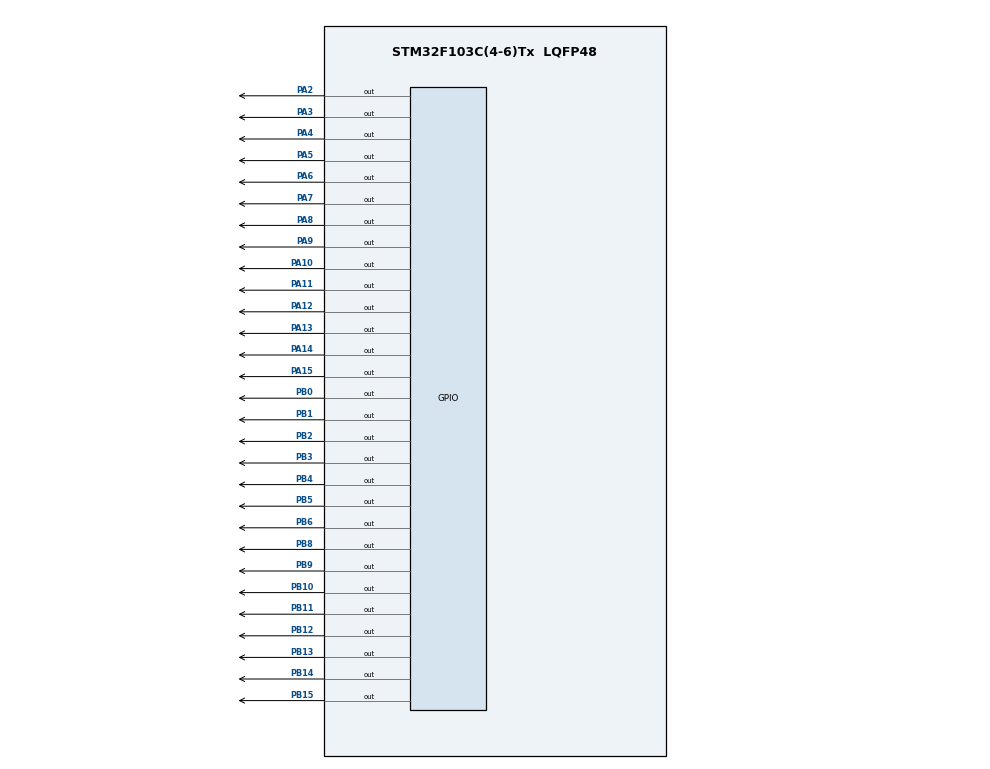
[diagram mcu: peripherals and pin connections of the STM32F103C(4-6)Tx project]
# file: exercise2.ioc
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Mcu.Family=STM32F1
Mcu.Name=STM32F103C(4-6)Tx
Mcu.Package=LQFP48
NVIC.PriorityGroup=NVIC_PRIORITYGROUP_4
NVIC.TIM2_IRQn=true\:0\:0\:false\:false\:true\:true\:true
PA10.Signal=GPIO_Output
PA11.Signal=GPIO_Output
PA12.Signal=GPIO_Output
PA13.Signal=GPIO_Output
PA14.Signal=GPIO_Output
PA15.Signal=GPIO_Output
PA2.Signal=GPIO_Output
PA3.Signal=GPIO_Output
PA4.Signal=GPIO_Output
PA5.Signal=GPIO_Output
PA6.Signal=GPIO_Output
PA7.Signal=GPIO_Output
PA8.Signal=GPIO_Output
PA9.Signal=GPIO_Output
PB0.Signal=GPIO_Output
PB1.Signal=GPIO_Output
PB10.Signal=GPIO_Output
PB11.Signal=GPIO_Output
PB12.Signal=GPIO_Output
PB13.Signal=GPIO_Output
PB14.Signal=GPIO_Output
PB15.Signal=GPIO_Output
PB2.Signal=GPIO_Output
PB3.Signal=GPIO_Output
PB4.Signal=GPIO_Output
PB5.Signal=GPIO_Output
PB6.Signal=GPIO_Output
PB8.Signal=GPIO_Output
PB9.Signal=GPIO_Output
ProjectManager.HeapSize=0x200
ProjectManager.StackSize=0x400
ProjectManager.TargetToolchain=STM32CubeIDE
RCC.APB1Freq_Value=8000000
RCC.APB2Freq_Value=8000000
TIM2.Period=9
TIM2.Prescaler=7999
VP_SYS_VS_ND.Mode=No_Debug
VP_TIM2_VS_ClockSourceINT.Mode=Internal
board=custom

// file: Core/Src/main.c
/* USER CODE BEGIN Header */
/**
  ******************************************************************************
  * @file           : main.c
  * @brief          : Main program body
  ******************************************************************************
  * @attention
  *
  * <h2><center>&copy; Copyright (c) 2021 STMicroelectronics.
  * All rights reserved.</center></h2>
  *
  * This software component is licensed by ST under BSD 3-Clause license,
  * the "License"; You may not use this file except in compliance with the
  * License. You may obtain a copy of the License at:
  *                        opensource.org/licenses/BSD-3-Clause
  *
  ******************************************************************************
  */
/* USER CODE END Header */
#include "main.h"

TIM_HandleTypeDef htim2;

void SystemClock_Config(void);
static void MX_GPIO_Init(void);
static void MX_TIM2_Init(void);

int hour = 15 , minute = 8 , second = 57;
int led_buffer [4] = {1 , 2 , 3 , 4};
void updateClockBuffer (){
	led_buffer[0] = hour/10;
	led_buffer[1] = hour%10;
	led_buffer[2] = minute/10;
	led_buffer[3] = minute%10;
}

// Exercise 6
  int timer0_counter = 0;
  int timer0_flag = 0;
  int timer1_counter = 0;
  int timer1_flag = 0;
  int timer2_counter = 0; // Time to update LED MATRIX
  int timer2_flag = 0; // Flag to update LED MATRIX
  int TIMER_CYCLE = 10;

  void setTimer0(int duration){
  	  timer0_counter = duration /TIMER_CYCLE;
  	  timer0_flag = 0;
  }

  void setTimer1(int duration){
	  timer1_counter = duration /TIMER_CYCLE;
	  timer1_flag = 0;
  }

  void setTimer2(int duration){
  	  timer2_counter = duration /TIMER_CYCLE;
  	  timer2_flag = 0;
    }

   void timer_run(){
	  if(timer0_counter > 0){
	   	  timer0_counter--;
	   	  if(timer0_counter == 0) timer0_flag = 1;
	  }

	  if(timer1_counter > 0){
		  timer1_counter--;
		  if(timer1_counter == 0) timer1_flag = 1;
	  }

	  if(timer2_counter > 0){
	  	  timer2_counter--;
	  	  if(timer2_counter == 0) timer2_flag = 1;
	  }

  }

  void display7SEG(int counter){
  	  switch(counter){
  	  case 0:
  		  HAL_GPIO_WritePin(GPIOB, GPIO_PIN_6, 1);
  		  HAL_GPIO_WritePin(GPIOB, GPIO_PIN_0|GPIO_PIN_1|GPIO_PIN_2|GPIO_PIN_3|GPIO_PIN_4|GPIO_PIN_5, 0);
  		  break;
  	  case 1:
  	  	HAL_GPIO_WritePin(GPIOB, GPIO_PIN_0|GPIO_PIN_3|GPIO_PIN_4|GPIO_PIN_5|GPIO_PIN_6, 1);
  	  	HAL_GPIO_WritePin(GPIOB, GPIO_PIN_1|GPIO_PIN_2, 0);
  	  	break;
  	  case 2:
  	  	HAL_GPIO_WritePin(GPIOB, GPIO_PIN_2|GPIO_PIN_5, 1);
  	  	HAL_GPIO_WritePin(GPIOB, GPIO_PIN_0|GPIO_PIN_1|GPIO_PIN_3|GPIO_PIN_4|GPIO_PIN_6, 0);
  	  	break;
  	  case 3:
  	  	HAL_GPIO_WritePin(GPIOB, GPIO_PIN_4|GPIO_PIN_5, 1);
  	  	HAL_GPIO_WritePin(GPIOB, GPIO_PIN_0|GPIO_PIN_1|GPIO_PIN_2|GPIO_PIN_3|GPIO_PIN_6, 0);
  	  	break;
  	  case 4:
  	  	HAL_GPIO_WritePin(GPIOB, GPIO_PIN_0|GPIO_PIN_3|GPIO_PIN_4, 1);
  	  	HAL_GPIO_WritePin(GPIOB, GPIO_PIN_1|GPIO_PIN_2|GPIO_PIN_5|GPIO_PIN_6, 0);
  	  	break;
  	  case 5:
  	  	HAL_GPIO_WritePin(GPIOB, GPIO_PIN_1|GPIO_PIN_4, 1);
  	  	HAL_GPIO_WritePin(GPIOB, GPIO_PIN_0|GPIO_PIN_2|GPIO_PIN_3|GPIO_PIN_5|GPIO_PIN_6, 0);
  	  	break;
  	  case 6:
  	  	HAL_GPIO_WritePin(GPIOB, GPIO_PIN_1, 1);
  	  	HAL_GPIO_WritePin(GPIOB, GPIO_PIN_0|GPIO_PIN_2|GPIO_PIN_3|GPIO_PIN_4|GPIO_PIN_5|GPIO_PIN_6, 0);
  	  	break;
  	  case 7:
  	  	HAL_GPIO_WritePin(GPIOB, GPIO_PIN_3|GPIO_PIN_4|GPIO_PIN_5|GPIO_PIN_6, 1);
  	  	HAL_GPIO_WritePin(GPIOB, GPIO_PIN_0|GPIO_PIN_1|GPIO_PIN_2, 0);
  	  	break;
  	  case 8:
  	  	HAL_GPIO_WritePin(GPIOB, GPIO_PIN_0|GPIO_PIN_1|GPIO_PIN_2|GPIO_PIN_3|GPIO_PIN_4|GPIO_PIN_5|GPIO_PIN_6, 0);
  	  	break;
  	  case 9:
  	  	HAL_GPIO_WritePin(GPIOB, GPIO_PIN_4, 1);
  	  	HAL_GPIO_WritePin(GPIOB, GPIO_PIN_0|GPIO_PIN_1|GPIO_PIN_2|GPIO_PIN_3|GPIO_PIN_5|GPIO_PIN_6, 0);
  	  	break;
  	  }
    }

void clearAllClock(){
	HAL_GPIO_WritePin(GPIOA, GPIO_PIN_6| GPIO_PIN_7| GPIO_PIN_8| GPIO_PIN_9, 1);
}

const int MAX_LED = 4;
int index_led = 0;
void update7SEG ( int index ) {
	switch ( index ) {
	case 0:
		// Display the first 7 SEG with led_buffer [0]
		clearAllClock();
		display7SEG(led_buffer[0]);
		HAL_GPIO_WritePin(GPIOA, GPIO_PIN_6, 0);
		break ;
	case 1:
		// Display the second 7 SEG with led_buffer [1]
		clearAllClock();
		display7SEG(led_buffer[1]);
		HAL_GPIO_WritePin(GPIOA, GPIO_PIN_7, 0);
		break ;
	case 2:
		// Display the third 7 SEG with led_buffer [2]
		clearAllClock();
		display7SEG(led_buffer[2]);
		HAL_GPIO_WritePin(GPIOA, GPIO_PIN_8, 0);
		break ;
	case 3:
		// Display the forth 7 SEG with led_buffer [3]
		clearAllClock();
		display7SEG(led_buffer[3]);
		HAL_GPIO_WritePin(GPIOA, GPIO_PIN_9, 0);
		break ;
	default :
		break ;
	}
}

int main(void)
{

  /* MCU Configuration--------------------------------------------------------*/

  /* Reset of all peripherals, Initializes the Flash interface and the Systick. */
  HAL_Init();

  /* Configure the system clock */
  SystemClock_Config();

  /* Initialize all configured peripherals */
  MX_GPIO_Init();
  MX_TIM2_Init();
  /* USER CODE BEGIN 2 */
  HAL_TIM_Base_Start_IT(&htim2);
  /* USER CODE END 2 */

  /* Infinite loop */
  /* USER CODE BEGIN WHILE */

  setTimer0(500);
  setTimer1(250);
  setTimer2(10); //10ms

//  Exercise 9
  const int MAX_LED_MATRIX = 8;
  int index_led_matrix = 0;
  int index_led_run = 0;
  uint8_t matrix_buffer[8] = {0x00, 0xFC, 0xFE, 0x33, 0x33, 0xFE, 0xFC, 0x0};

  void clearMatrix(){
	  HAL_GPIO_WritePin(GPIOA, GPIO_PIN_2|GPIO_PIN_3|GPIO_PIN_10
			  |GPIO_PIN_11|GPIO_PIN_12|GPIO_PIN_13|GPIO_PIN_14|GPIO_PIN_15, 1);
  }

  void updateLEDMatrix(int index, int index_run){
	  GPIOB->BSRR = 0b1111111100000000;
	  GPIOB->BRR = matrix_buffer[index + index_run] << 8 ;
	  clearMatrix();
  	  switch(index){
  	  case 0:
  		  HAL_GPIO_WritePin(GPIOA, GPIO_PIN_2, 0);
  		  break;
  	  case 1:
  		  HAL_GPIO_WritePin(GPIOA, GPIO_PIN_3, 0);
  		  break ;
  	  case 2:
  		  HAL_GPIO_WritePin(GPIOA, GPIO_PIN_10, 0);
  		  break ;
  	  case 3:
  		  HAL_GPIO_WritePin(GPIOA, GPIO_PIN_11, 0);
  		  break ;
  	  case 4:
  		  HAL_GPIO_WritePin(GPIOA, GPIO_PIN_12, 0);
  		  break ;
  	  case 5:
  		  HAL_GPIO_WritePin(GPIOA, GPIO_PIN_13, 0);
  		  break ;
  	  case 6:
  		  HAL_GPIO_WritePin(GPIOA, GPIO_PIN_14, 0);
  		  break ;
  	  case 7:
  		  HAL_GPIO_WritePin(GPIOA, GPIO_PIN_15, 0);
  		  break ;
  	  default :
  		  break ;

  	  }
    }

  while (1)
  {

	  if(timer0_flag == 1){
		  HAL_GPIO_TogglePin(GPIOA, GPIO_PIN_5);
		  HAL_GPIO_TogglePin(GPIOA, GPIO_PIN_4);
		  setTimer0(500);
	  }

  	  if(timer1_flag == 1){

		  update7SEG(index_led);
		  index_led++;
		  if(index_led >= MAX_LED){
			  index_led =0;
			  second ++;
			  if ( second >= 60) {
				  second = 0;
			  	  minute ++;
			  }
			  if( minute >= 60) {
			  	  minute = 0;
			  	  hour ++;
			  }
			  if( hour >=24) {
			  	  hour = 0;
			  }
		  }
		  updateClockBuffer () ;
	  	  setTimer1(250);
	  }

  	  if(timer2_flag == 1){

  		  if(index_led_matrix + index_led_run >=  MAX_LED_MATRIX){
  			updateLEDMatrix(index_led_matrix, index_led_run - MAX_LED_MATRIX);
  		  }
  		  else updateLEDMatrix(index_led_matrix, index_led_run);

  		  index_led_matrix++;
  		  if(index_led_matrix >= MAX_LED_MATRIX){
  			  index_led_matrix = 0;

  			  index_led_run ++;
  			  if(index_led_run >= MAX_LED_MATRIX){
  				  index_led_run = 0;
  			  }

  		  }

  		  setTimer2(10);
  	  }
  }

}

void SystemClock_Config(void)
{
  RCC_OscInitTypeDef RCC_OscInitStruct = {0};
  RCC_ClkInitTypeDef RCC_ClkInitStruct = {0};

  /** Initializes the RCC Oscillators according to the specified parameters
  * in the RCC_OscInitTypeDef structure.
  */
  RCC_OscInitStruct.OscillatorType = RCC_OSCILLATORTYPE_HSI;
  RCC_OscInitStruct.HSIState = RCC_HSI_ON;
  RCC_OscInitStruct.HSICalibrationValue = RCC_HSICALIBRATION_DEFAULT;
  RCC_OscInitStruct.PLL.PLLState = RCC_PLL_NONE;
  if (HAL_RCC_OscConfig(&RCC_OscInitStruct) != HAL_OK)
  {
    Error_Handler();
  }
  /** Initializes the CPU, AHB and APB buses clocks
  */
  RCC_ClkInitStruct.ClockType = RCC_CLOCKTYPE_HCLK|RCC_CLOCKTYPE_SYSCLK
                              |RCC_CLOCKTYPE_PCLK1|RCC_CLOCKTYPE_PCLK2;
  RCC_ClkInitStruct.SYSCLKSource = RCC_SYSCLKSOURCE_HSI;
  RCC_ClkInitStruct.AHBCLKDivider = RCC_SYSCLK_DIV1;
  RCC_ClkInitStruct.APB1CLKDivider = RCC_HCLK_DIV1;
  RCC_ClkInitStruct.APB2CLKDivider = RCC_HCLK_DIV1;

  if (HAL_RCC_ClockConfig(&RCC_ClkInitStruct, FLASH_LATENCY_0) != HAL_OK)
  {
    Error_Handler();
  }
}

static void MX_TIM2_Init(void)
{

  TIM_ClockConfigTypeDef sClockSourceConfig = {0};
  TIM_MasterConfigTypeDef sMasterConfig = {0};

  htim2.Instance = TIM2;
  htim2.Init.Prescaler = 7999;
  htim2.Init.CounterMode = TIM_COUNTERMODE_UP;
  htim2.Init.Period = 9;
  htim2.Init.ClockDivision = TIM_CLOCKDIVISION_DIV1;
  htim2.Init.AutoReloadPreload = TIM_AUTORELOAD_PRELOAD_DISABLE;
  if (HAL_TIM_Base_Init(&htim2) != HAL_OK)
  {
    Error_Handler();
  }
  sClockSourceConfig.ClockSource = TIM_CLOCKSOURCE_INTERNAL;
  if (HAL_TIM_ConfigClockSource(&htim2, &sClockSourceConfig) != HAL_OK)
  {
    Error_Handler();
  }
  sMasterConfig.MasterOutputTrigger = TIM_TRGO_RESET;
  sMasterConfig.MasterSlaveMode = TIM_MASTERSLAVEMODE_DISABLE;
  if (HAL_TIMEx_MasterConfigSynchronization(&htim2, &sMasterConfig) != HAL_OK)
  {
    Error_Handler();
  }

}

static void MX_GPIO_Init(void)
{
  GPIO_InitTypeDef GPIO_InitStruct = {0};

  /* GPIO Ports Clock Enable */
  __HAL_RCC_GPIOA_CLK_ENABLE();
  __HAL_RCC_GPIOB_CLK_ENABLE();

  /*Configure GPIO pin Output Level */
  HAL_GPIO_WritePin(GPIOA, GPIO_PIN_2|GPIO_PIN_3|GPIO_PIN_4|GPIO_PIN_5
                          |GPIO_PIN_6|GPIO_PIN_7|GPIO_PIN_8|GPIO_PIN_9
                          |GPIO_PIN_10|GPIO_PIN_11|GPIO_PIN_12|GPIO_PIN_13
                          |GPIO_PIN_14|GPIO_PIN_15, GPIO_PIN_RESET);

  /*Configure GPIO pin Output Level */
  HAL_GPIO_WritePin(GPIOB, GPIO_PIN_0|GPIO_PIN_1|GPIO_PIN_2|GPIO_PIN_10
                          |GPIO_PIN_11|GPIO_PIN_12|GPIO_PIN_13|GPIO_PIN_14
                          |GPIO_PIN_15|GPIO_PIN_3|GPIO_PIN_4|GPIO_PIN_5
                          |GPIO_PIN_6|GPIO_PIN_8|GPIO_PIN_9, GPIO_PIN_RESET);

  /*Configure GPIO pins : PA2 PA3 PA4 PA5
                           PA6 PA7 PA8 PA9
                           PA10 PA11 PA12 PA13
                           PA14 PA15 */
  GPIO_InitStruct.Pin = GPIO_PIN_2|GPIO_PIN_3|GPIO_PIN_4|GPIO_PIN_5
                          |GPIO_PIN_6|GPIO_PIN_7|GPIO_PIN_8|GPIO_PIN_9
                          |GPIO_PIN_10|GPIO_PIN_11|GPIO_PIN_12|GPIO_PIN_13
                          |GPIO_PIN_14|GPIO_PIN_15;
  GPIO_InitStruct.Mode = GPIO_MODE_OUTPUT_PP;
  GPIO_InitStruct.Pull = GPIO_NOPULL;
  GPIO_InitStruct.Speed = GPIO_SPEED_FREQ_LOW;
  HAL_GPIO_Init(GPIOA, &GPIO_InitStruct);

  /*Configure GPIO pins : PB0 PB1 PB2 PB10
                           PB11 PB12 PB13 PB14
                           PB15 PB3 PB4 PB5
                           PB6 PB8 PB9 */
  GPIO_InitStruct.Pin = GPIO_PIN_0|GPIO_PIN_1|GPIO_PIN_2|GPIO_PIN_10
                          |GPIO_PIN_11|GPIO_PIN_12|GPIO_PIN_13|GPIO_PIN_14
                          |GPIO_PIN_15|GPIO_PIN_3|GPIO_PIN_4|GPIO_PIN_5
                          |GPIO_PIN_6|GPIO_PIN_8|GPIO_PIN_9;
  GPIO_InitStruct.Mode = GPIO_MODE_OUTPUT_PP;
  GPIO_InitStruct.Pull = GPIO_NOPULL;
  GPIO_InitStruct.Speed = GPIO_SPEED_FREQ_LOW;
  HAL_GPIO_Init(GPIOB, &GPIO_InitStruct);

}

/* USER CODE BEGIN 4 */

void HAL_TIM_PeriodElapsedCallback ( TIM_HandleTypeDef * htim ){

	timer_run(); // function for update 7 SEG

}

/* USER CODE END 4 */

void Error_Handler(void)
{
  __disable_irq();
  while (1)
  {
  }
}

/************************ (C) COPYRIGHT STMicroelectronics *****END OF FILE****/
